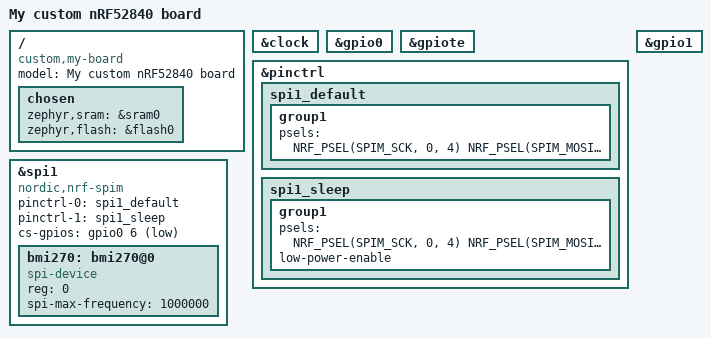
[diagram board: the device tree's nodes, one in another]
/dts-v1/;

#include <zephyr/dt-bindings/pinctrl/nrf-pinctrl.h>
#include <nordic/nrf52840_qiaa.dtsi>
#include <nordic/nrf52840_partition.dtsi>

/ {
    model = "My custom nRF52840 board";
    compatible = "custom,my-board";

    chosen {
        zephyr,sram = &sram0;
        zephyr,flash = &flash0;
    };
};

&clock {
    status = "okay";
};

&gpio0 {
    status = "okay";
};

&gpiote {
    status = "okay";
};

&pinctrl {

    spi1_default: spi1_default {
        group1 {
            psels = <
                NRF_PSEL(SPIM_SCK, 0, 4)
                NRF_PSEL(SPIM_MOSI, 0, 27)
                NRF_PSEL(SPIM_MISO, 0, 26)
            >;
        };
    };

    spi1_sleep: spi1_sleep {
        group1 {
            psels = <
                NRF_PSEL(SPIM_SCK, 0, 4)
                NRF_PSEL(SPIM_MOSI, 0, 27)
                NRF_PSEL(SPIM_MISO, 0, 26)
            >;

            low-power-enable;
        };
    };
};

&spi1 {
    compatible = "nordic,nrf-spim";
    status = "okay";

    pinctrl-0 = <&spi1_default>;
    pinctrl-1 = <&spi1_sleep>;
    pinctrl-names = "default", "sleep";

    cs-gpios = <&gpio0 6 GPIO_ACTIVE_LOW>;

    bmi270: bmi270@0 {
        compatible = "spi-device";
        reg = <0>;
        spi-max-frequency = <1000000>;
    };
};

&gpio1 {
    status = "okay";
};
